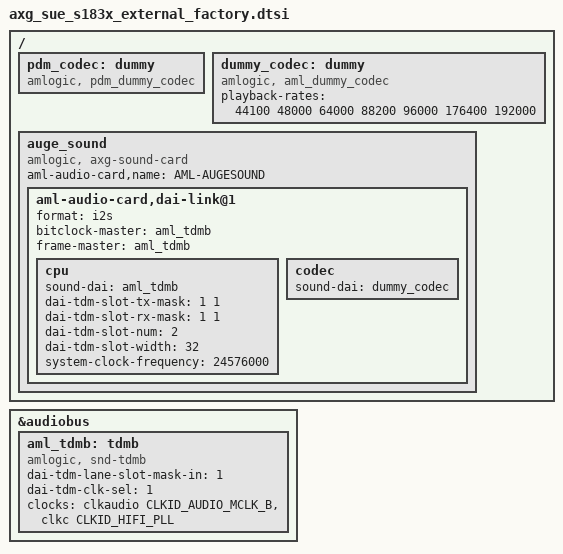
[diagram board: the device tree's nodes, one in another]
/*
 * arch/arm64/boot/dts/amlogic/axg_sue_s183x_external_factory.dtsi
 *
 * Copyright (C) 2017 Amlogic, Inc. All rights reserved.
 *
 * This program is free software; you can redistribute it and/or modify
 * it under the terms of the GNU General Public License as published by
 * the Free Software Foundation; either version 2 of the License, or
 * (at your option) any later version.
 *
 * This program is distributed in the hope that it will be useful, but WITHOUT
 * ANY WARRANTY; without even the implied warranty of MERCHANTABILITY or
 * FITNESS FOR A PARTICULAR PURPOSE.  See the GNU General Public License for
 * more details.
 *
 */


/*
 * DT for factory configuration of Stream183x external IOs.
 */


/ {
	pdm_codec:dummy{
		#sound-dai-cells = <0>;
		compatible = "amlogic, pdm_dummy_codec";
		status = "okay";
	};

	dummy_codec:dummy{
		#sound-dai-cells = <0>;
		compatible = "amlogic, aml_dummy_codec";
		playback-rates = <44100 48000 64000 88200 96000 176400 192000>;
		status = "okay";
	};

	auge_sound {
		compatible = "amlogic, axg-sound-card";
		aml-audio-card,name = "AML-AUGESOUND";

		aml-audio-card,dai-link@1 {
			format = "i2s";
			bitclock-master = <&aml_tdmb>;
			frame-master = <&aml_tdmb>;
			cpu {
				sound-dai = <&aml_tdmb>;
				dai-tdm-slot-tx-mask = <1 1>;
				dai-tdm-slot-rx-mask = <1 1>;
				dai-tdm-slot-num = <2>;
				dai-tdm-slot-width = <32>;
				system-clock-frequency = <24576000>;
			};
			codec {
				sound-dai = <&dummy_codec>;
			};
		};
	};
};

&audiobus {
	aml_tdmb: tdmb {
		compatible = "amlogic, snd-tdmb";
		#sound-dai-cells = <0>;
		dai-tdm-lane-slot-mask-in = <1>;
		dai-tdm-clk-sel = <1>;
		clocks = <&clkaudio CLKID_AUDIO_MCLK_B
				&clkc CLKID_HIFI_PLL>;
		clock-names = "mclk", "clk_srcpll";
		status = "okay";
	};
};
